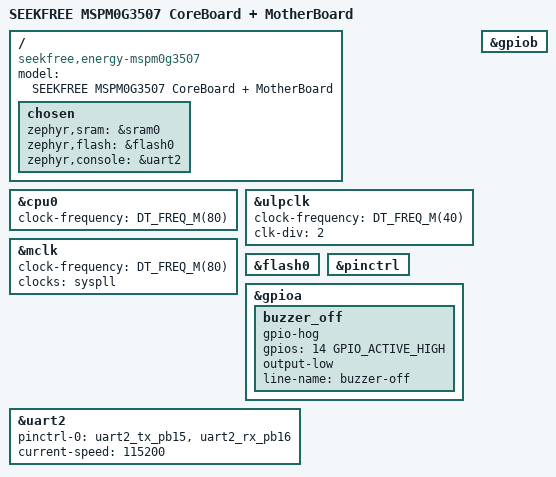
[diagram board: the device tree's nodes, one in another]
/dts-v1/;
#include <ti/mspm0/g/mspm0g3507.dtsi>
#include <ti/mspm0/g/mspm0g1x0x_g3x0x-pinctrl.dtsi>
#include <zephyr/dt-bindings/clock/mspm0_clock.h>
#include <zephyr/dt-bindings/gpio/gpio.h>

/ {
	model = "SEEKFREE MSPM0G3507 CoreBoard + MotherBoard";
	compatible = "seekfree,energy-mspm0g3507";
	chosen {
		zephyr,sram = &sram0;
		zephyr,flash = &flash0;
		zephyr,console = &uart2;
	};
};
&cpu0 { clock-frequency = <DT_FREQ_M(80)>; };
&ulpclk { clock-frequency = <DT_FREQ_M(40)>; clk-div = <2>; };
&mclk { clock-frequency = <DT_FREQ_M(80)>; clocks = <&syspll>; };
&flash0 { status = "okay"; };
&pinctrl { status = "okay"; };
&gpioa {
	status = "okay";
	/* PA14 also drives core LED2. Keep the motherboard buzzer OFF. */
	buzzer_off {
		gpio-hog;
		gpios = <14 GPIO_ACTIVE_HIGH>;
		output-low;
		line-name = "buzzer-off";
	};
};
&gpiob { status = "okay"; };
&uart2 {
	pinctrl-0 = <&uart2_tx_pb15 &uart2_rx_pb16>;
	pinctrl-names = "default";
	current-speed = <115200>;
	status = "okay";
};
